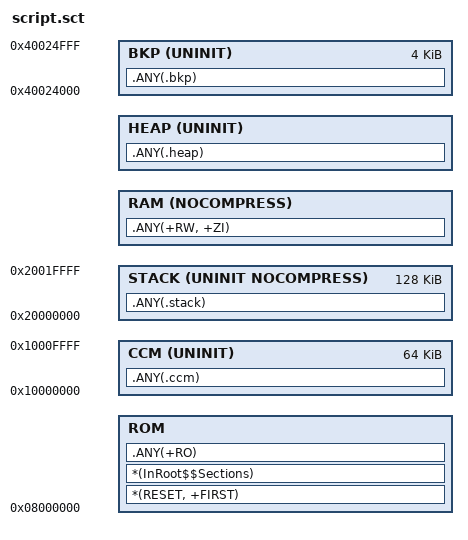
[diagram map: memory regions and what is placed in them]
/*******************************************************************************
@file     stm32f4xx.sct
@author   Rajmund Szymanski
@date     11.12.2019
@brief    Scatter file for STM32F407VG device with 1024KB FLASH and 192KB RAM
*******************************************************************************/

FLASH 0x08000000 0x00100000
{
	ROM +0
	{
		*(RESET, +FIRST)
		*(InRoot$$Sections)
		.ANY(+RO)
	}

	CCM 0x10000000 UNINIT 0x00010000
	{
		.ANY(.ccm)
	}

	BKP 0x40024000 UNINIT 0x00001000
	{
		.ANY(.bkp)
	}

	STACK 0x20000000 UNINIT NOCOMPRESS 0x00020000
	{
		.ANY(.stack)
	}

	RAM ALIGNEXPR(+0, 8) NOCOMPRESS
	{
		.ANY(+RW, +ZI)
	}

	HEAP ALIGNEXPR(+0, 8) UNINIT
	{
		.ANY(.heap)
	}
}
